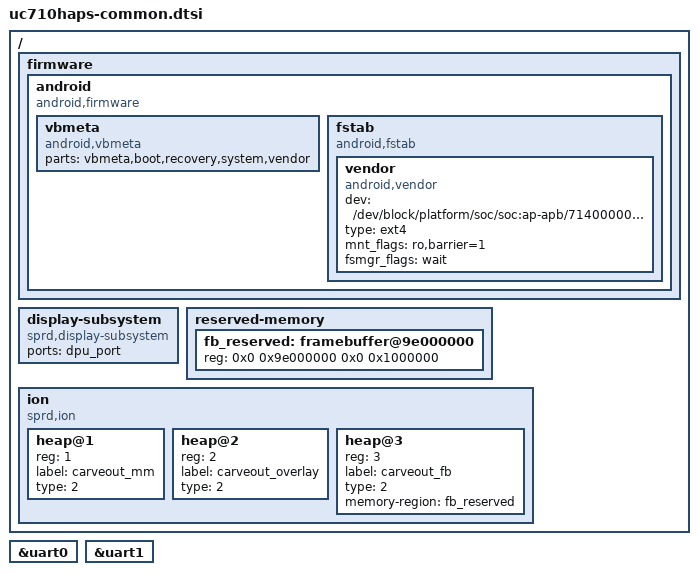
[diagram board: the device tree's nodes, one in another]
/*
 * Spreadtrum UD710 board common DTS file
 *
 * Copyright (C) 2018, Spreadtrum Communications Inc.
 *
 * This file is licensed under a dual GPLv2 or X11 license.
 */

/ {
	firmware {
		android {
			compatible = "android,firmware";

			vbmeta {
				compatible = "android,vbmeta";
				parts = "vbmeta,boot,recovery,system,vendor";
			};

			fstab {
				compatible = "android,fstab";
				vendor {
					compatible = "android,vendor";
					dev = "/dev/block/platform/soc/soc:ap-apb/71400000.sdio/by-name/vendor";
					type = "ext4";
					mnt_flags = "ro,barrier=1";
					fsmgr_flags = "wait";
				};
			};
		};
	};

	display-subsystem {
		compatible = "sprd,display-subsystem";
		ports = <&dpu_port>;
	};

	reserved-memory {
		#address-cells = <2>;
		#size-cells = <2>;
		ranges;

		fb_reserved: framebuffer@9e000000{
			reg = <0x0 0x9e000000 0x0 0x1000000>;
		};
	};

	ion {
		compatible = "sprd,ion";
		#address-cells = <1>;
		#size-cells = <0>;

		heap@1 {
			reg = <1>;
			label = "carveout_mm";
			type = <2>;
		};

		heap@2 {
			reg = <2>;
			label = "carveout_overlay";
			type = <2>;
		};

		heap@3 {
			reg = <3>;
			label = "carveout_fb";
			type = <2>;
			memory-region = <&fb_reserved>;
		};
	};
};

&uart0 {
	status = "okay";
};
&uart1 {
	status = "okay";
};
